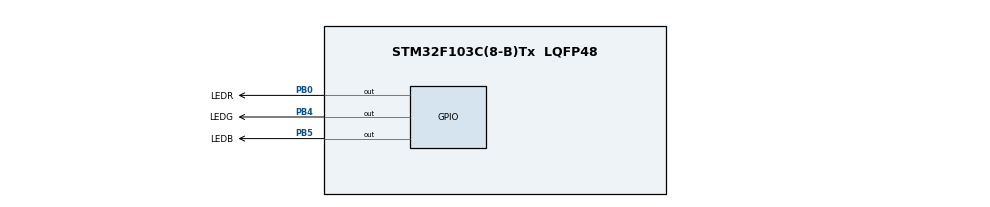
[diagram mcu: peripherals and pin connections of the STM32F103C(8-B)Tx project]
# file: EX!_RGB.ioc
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Mcu.Family=STM32F1
Mcu.Name=STM32F103C(8-B)Tx
Mcu.Package=LQFP48
NVIC.PriorityGroup=NVIC_PRIORITYGROUP_4
PB0.GPIO_Label=LEDR
PB0.GPIO_Speed=GPIO_SPEED_FREQ_HIGH
PB0.PinState=GPIO_PIN_SET
PB0.Signal=GPIO_Output
PB4.GPIO_Label=LEDG
PB4.GPIO_Speed=GPIO_SPEED_FREQ_HIGH
PB4.PinState=GPIO_PIN_SET
PB4.Signal=GPIO_Output
PB5.GPIO_Label=LEDB
PB5.GPIO_Speed=GPIO_SPEED_FREQ_HIGH
PB5.PinState=GPIO_PIN_SET
PB5.Signal=GPIO_Output
PD0-OSC_IN.Mode=HSE-External-Oscillator
PD0-OSC_IN.Signal=RCC_OSC_IN
PD1-OSC_OUT.Mode=HSE-External-Oscillator
PD1-OSC_OUT.Signal=RCC_OSC_OUT
ProjectManager.HeapSize=0x200
ProjectManager.StackSize=0x400
ProjectManager.TargetToolchain=MDK-ARM V5.32
RCC.AHBFreq_Value=72000000
RCC.APB1CLKDivider=RCC_HCLK_DIV2
RCC.APB1Freq_Value=36000000
RCC.APB1TimFreq_Value=72000000
RCC.APB2Freq_Value=72000000
RCC.APB2TimFreq_Value=72000000
RCC.HCLKFreq_Value=72000000
RCC.PLLMUL=RCC_PLL_MUL9
RCC.PLLSourceVirtual=RCC_PLLSOURCE_HSE
RCC.SYSCLKFreq_VALUE=72000000
RCC.SYSCLKSource=RCC_SYSCLKSOURCE_PLLCLK
RCC.USBFreq_Value=72000000
VP_SYS_VS_ND.Mode=No_Debug
board=custom

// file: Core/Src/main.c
/* USER CODE BEGIN Header */
/**
  ******************************************************************************
  * @file           : main.c
  * @brief          : Main program body
  ******************************************************************************
  * @attention
  *
  * Copyright (c) 2022 STMicroelectronics.
  * All rights reserved.
  *
  * This software is licensed under terms that can be found in the LICENSE file
  * in the root directory of this software component.
  * If no LICENSE file comes with this software, it is provided AS-IS.
  *
  ******************************************************************************
  */
/* USER CODE END Header */
#include "main.h"
#include "gpio.h"

void SystemClock_Config(void);

int main(void)
{

  /* MCU Configuration--------------------------------------------------------*/

  /* Reset of all peripherals, Initializes the Flash interface and the Systick. */
  LL_APB2_GRP1_EnableClock(LL_APB2_GRP1_PERIPH_AFIO);
  LL_APB1_GRP1_EnableClock(LL_APB1_GRP1_PERIPH_PWR);

  /* System interrupt init*/
  NVIC_SetPriorityGrouping(NVIC_PRIORITYGROUP_4);

  /* SysTick_IRQn interrupt configuration */
  NVIC_SetPriority(SysTick_IRQn, NVIC_EncodePriority(NVIC_GetPriorityGrouping(),15, 0));

  /** DISABLE: JTAG-DP Disabled and SW-DP Disabled
  */
  LL_GPIO_AF_DisableRemap_SWJ();

  /* Configure the system clock */
  SystemClock_Config();

  /* Initialize all configured peripherals */
  MX_GPIO_Init();

  /* Infinite loop */
  /* USER CODE BEGIN WHILE */
  while (1)
  {
		LL_GPIO_ResetOutputPin(LEDB_GPIO_Port,LEDB_Pin);
		LL_mDelay(200);
		LL_GPIO_SetOutputPin(LEDB_GPIO_Port,LEDB_Pin);
		LL_mDelay(500);

    /* USER CODE END WHILE */

  }
}

void SystemClock_Config(void)
{
  LL_FLASH_SetLatency(LL_FLASH_LATENCY_2);
  while(LL_FLASH_GetLatency()!= LL_FLASH_LATENCY_2)
  {
  }
  LL_RCC_HSE_Enable();

   /* Wait till HSE is ready */
  while(LL_RCC_HSE_IsReady() != 1)
  {

  }
  LL_RCC_PLL_ConfigDomain_SYS(LL_RCC_PLLSOURCE_HSE_DIV_1, LL_RCC_PLL_MUL_9);
  LL_RCC_PLL_Enable();

   /* Wait till PLL is ready */
  while(LL_RCC_PLL_IsReady() != 1)
  {

  }
  LL_RCC_SetAHBPrescaler(LL_RCC_SYSCLK_DIV_1);
  LL_RCC_SetAPB1Prescaler(LL_RCC_APB1_DIV_2);
  LL_RCC_SetAPB2Prescaler(LL_RCC_APB2_DIV_1);
  LL_RCC_SetSysClkSource(LL_RCC_SYS_CLKSOURCE_PLL);

   /* Wait till System clock is ready */
  while(LL_RCC_GetSysClkSource() != LL_RCC_SYS_CLKSOURCE_STATUS_PLL)
  {

  }
  LL_Init1msTick(72000000);
  LL_SetSystemCoreClock(72000000);
}

void Error_Handler(void)
{
  __disable_irq();
  while (1)
  {
  }
}
